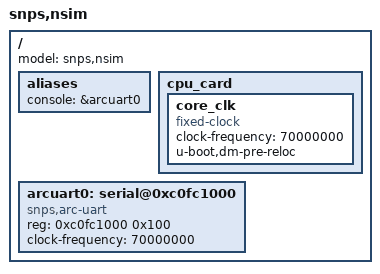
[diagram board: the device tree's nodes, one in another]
// SPDX-License-Identifier: GPL-2.0+
/*
 * Copyright (C) 2015-2016 Synopsys, Inc. (www.synopsys.com)
 */
/dts-v1/;

#include "skeleton.dtsi"

/ {
	model = "snps,nsim";

	aliases {
		console = &arcuart0;
	};

	cpu_card {
		core_clk: core_clk {
			#clock-cells = <0>;
			compatible = "fixed-clock";
			clock-frequency = <70000000>;
			u-boot,dm-pre-reloc;
		};
	};

	arcuart0: serial@0xc0fc1000 {
		compatible = "snps,arc-uart";
		reg = <0xc0fc1000 0x100>;
		clock-frequency = <70000000>;
	};

};
